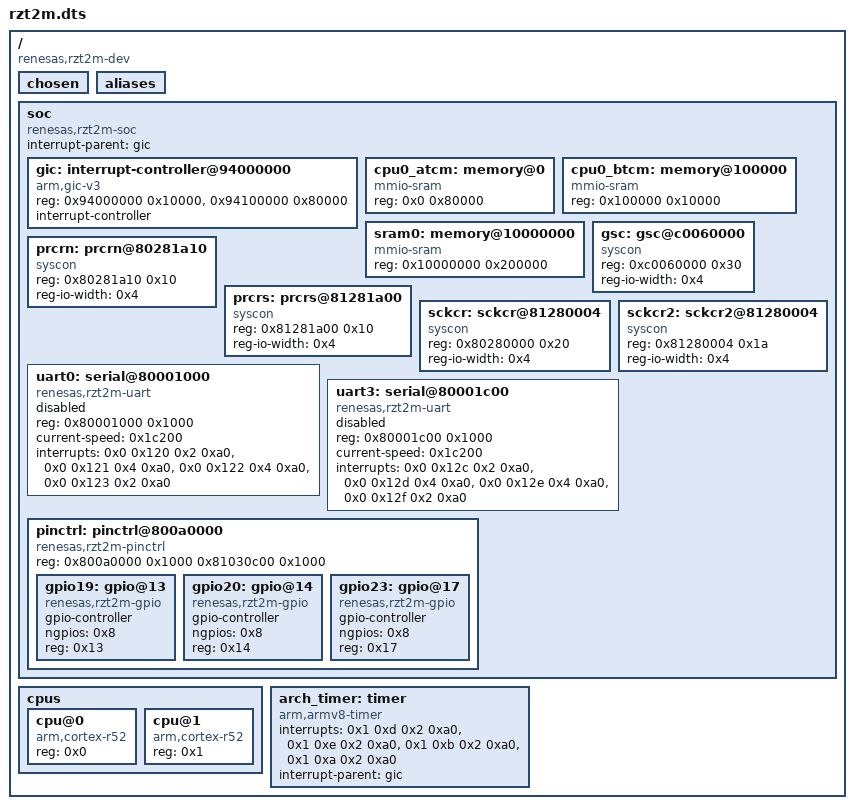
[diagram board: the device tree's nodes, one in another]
/dts-v1/;

/ {
	#address-cells = < 0x1 >;
	#size-cells = < 0x1 >;
	compatible = "renesas,rzt2m-dev";
	chosen {
	};
	aliases {
	};
	soc {
		#address-cells = < 0x1 >;
		#size-cells = < 0x1 >;
		compatible = "renesas,rzt2m-soc";
		ranges;
		interrupt-parent = < &gic >;
		gic: interrupt-controller@94000000 {
			compatible = "arm,gic-v3", "arm,gic";
			reg = < 0x94000000 0x10000 >, < 0x94100000 0x80000 >;
			interrupt-controller;
			#interrupt-cells = < 0x4 >;
			status = "okay";
			phandle = < 0x1 >;
		};
		cpu0_atcm: memory@0 {
			compatible = "mmio-sram";
			reg = < 0x0 0x80000 >;
		};
		cpu0_btcm: memory@100000 {
			compatible = "mmio-sram";
			reg = < 0x100000 0x10000 >;
		};
		sram0: memory@10000000 {
			compatible = "mmio-sram";
			reg = < 0x10000000 0x200000 >;
		};
		gsc: gsc@c0060000 {
			compatible = "syscon";
			reg = < 0xc0060000 0x30 >;
			reg-io-width = < 0x4 >;
		};
		prcrn: prcrn@80281a10 {
			compatible = "syscon";
			reg = < 0x80281a10 0x10 >;
			reg-io-width = < 0x4 >;
		};
		prcrs: prcrs@81281a00 {
			compatible = "syscon";
			reg = < 0x81281a00 0x10 >;
			reg-io-width = < 0x4 >;
		};
		sckcr: sckcr@81280004 {
			compatible = "syscon";
			reg = < 0x80280000 0x20 >;
			reg-io-width = < 0x4 >;
		};
		sckcr2: sckcr2@81280004 {
			compatible = "syscon";
			reg = < 0x81280004 0x1a >;
			reg-io-width = < 0x4 >;
		};
		uart0: serial@80001000 {
			compatible = "renesas,rzt2m-uart";
			reg = < 0x80001000 0x1000 >;
			current-speed = < 0x1c200 >;
			interrupts = < 0x0 0x120 0x2 0xa0 >, < 0x0 0x121 0x4 0xa0 >, < 0x0 0x122 0x4 0xa0 >, < 0x0 0x123 0x2 0xa0 >;
			interrupt-names = "rx_err", "rx", "tx", "tx_end";
			status = "disabled";
		};
		uart3: serial@80001c00 {
			compatible = "renesas,rzt2m-uart";
			reg = < 0x80001c00 0x1000 >;
			current-speed = < 0x1c200 >;
			interrupts = < 0x0 0x12c 0x2 0xa0 >, < 0x0 0x12d 0x4 0xa0 >, < 0x0 0x12e 0x4 0xa0 >, < 0x0 0x12f 0x2 0xa0 >;
			interrupt-names = "rx_err", "rx", "tx", "tx_end";
			status = "disabled";
		};
		pinctrl: pinctrl@800a0000 {
			compatible = "renesas,rzt2m-pinctrl";
			reg = < 0x800a0000 0x1000 0x81030c00 0x1000 >;
			reg-names = "port_nsr", "ptadr";
			#address-cells = < 0x1 >;
			#size-cells = < 0x0 >;
			gpio19: gpio@13 {
				compatible = "renesas,rzt2m-gpio";
				gpio-controller;
				#gpio-cells = < 0x2 >;
				ngpios = < 0x8 >;
				reg = < 0x13 >;
			};
			gpio20: gpio@14 {
				compatible = "renesas,rzt2m-gpio";
				gpio-controller;
				#gpio-cells = < 0x2 >;
				ngpios = < 0x8 >;
				reg = < 0x14 >;
			};
			gpio23: gpio@17 {
				compatible = "renesas,rzt2m-gpio";
				gpio-controller;
				#gpio-cells = < 0x2 >;
				ngpios = < 0x8 >;
				reg = < 0x17 >;
			};
		};
	};
	cpus {
		#address-cells = < 0x1 >;
		#size-cells = < 0x0 >;
		cpu@0 {
			device_type = "cpu";
			compatible = "arm,cortex-r52";
			reg = < 0x0 >;
		};
		cpu@1 {
			device_type = "cpu";
			compatible = "arm,cortex-r52";
			reg = < 0x1 >;
		};
	};
	arch_timer: timer {
		compatible = "arm,armv8-timer";
		interrupts = < 0x1 0xd 0x2 0xa0 >, < 0x1 0xe 0x2 0xa0 >, < 0x1 0xb 0x2 0xa0 >, < 0x1 0xa 0x2 0xa0 >;
		interrupt-parent = < &gic >;
	};
};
